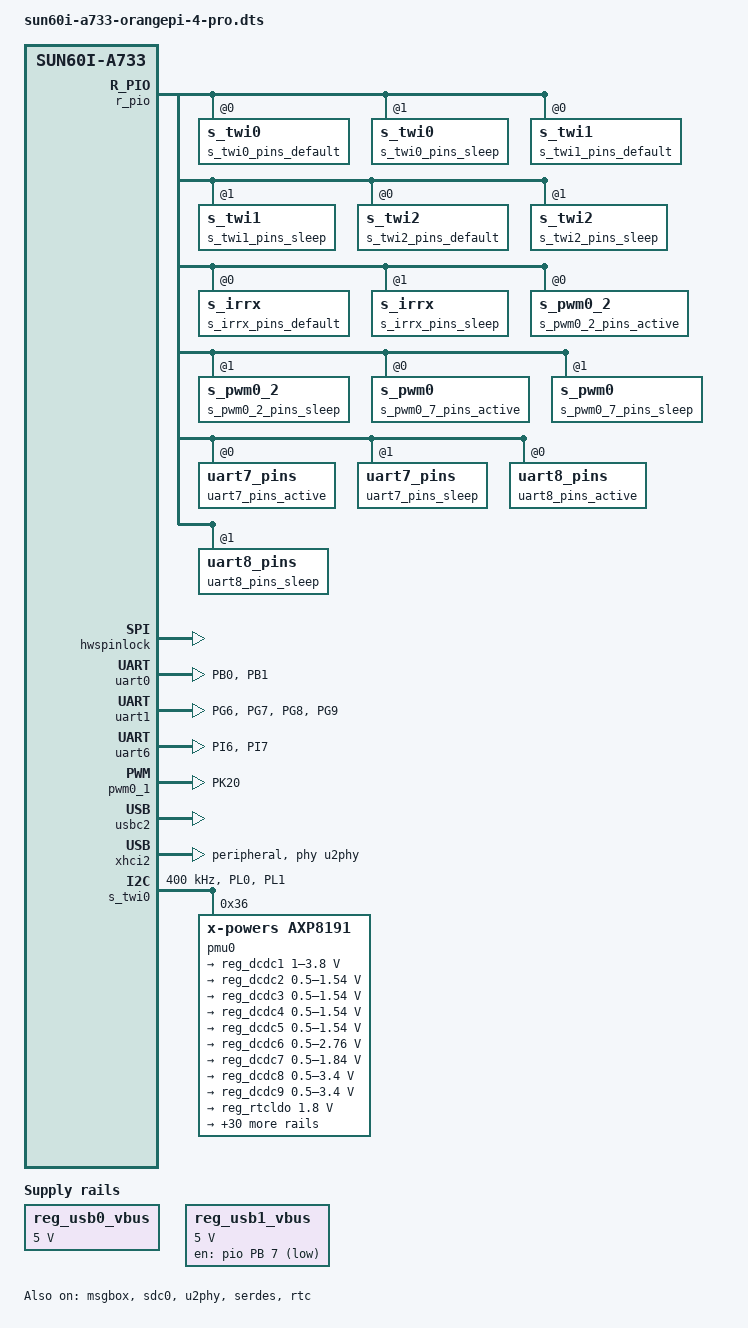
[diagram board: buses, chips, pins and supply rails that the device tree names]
// SPDX-License-Identifier: (GPL-2.0+ or MIT)
//
// Thinned for USB-device-only programmer image (FunctionFS bulk in/out only).
//
// KEPT:  usbc2/xhci2 (dr_mode=peripheral, USB3.0 device on a600000-xhci),
//        u2phy, serdes/combophy0 (USB3 serdes), sdc0, sdc2, ufs,
//        pio/r_pio (GPIO), twi* / s_twi* (I2C), uart* (UART).
//
// USB gadget: ONLY FunctionFS (CONFIG_USB_F_FS + CONFIG_USB_CONFIGFS_F_FS).
//   Dropped: ACM, SERIAL, NCM, RNDIS, MASS_STORAGE, UAC1, UVC, HID, PRINTER,
//            USB_ROLE_SWITCH, USB_NET, NET/INET core (no RNDIS/NCM consumer).
//
// DISABLED per build spec:
//   - GPU, NPU
//   - Display (dsi0 already commented out; touchscreen disabled in twi5)
//   - Ethernet / WiFi / BT (addr_mgt + all related PHY/MAC drivers off in .config)
//   - Camera (vind0/csi*/mipi* already commented out)
//   - Sound (es8388 in twi7 disabled; ac101 in s_twi2 already disabled)
//   - PCIe host (AW_PCIE_RC off in .config; serdes retained for USB3)
//   - SPI-NOR (spi0 disabled; AW_MTD_SPI_NOR off in .config)
//   - USB host mode (EHCI/OHCI/XHCI HCDs off in .config; only DWC3-peripheral kept)
//   - LED (gpio-leds status_led disabled; ledc disabled; CONFIG_LEDS_* off in .config)
//   - sdc3 (eMMC) — not in keep-list; only sdc0 / sdc2 / UFS retained
//

/dts-v1/;

#include "sun60iw2p1.dtsi"
//#define TYPEC_DP 1
/{
        board = "A733";
        compatible = "xunlong,orangepi-4-pro", "arm,sun60iw2p1";
        aliases {
                arisc-config = &arisc_config;
                pmu0 = &pmu0;
                bat_supply = &bat_power_supply;
        };

        reg_usb0_vbus: usb0-vbus {
        compatible = "regulator-fixed";
        regulator-name = "usb0-vbus";
        regulator-min-microvolt = <5000000>;
        regulator-max-microvolt = <5000000>;
        //gpio = <&r_pio PL 2 GPIO_ACTIVE_HIGH>;  ← COMMENTED OUT
        //enable-active-high;
        };

        reg_usb1_vbus: usb1-vbus {
                compatible = "regulator-fixed";
                regulator-name = "usb1-vbus";
                regulator-min-microvolt = <5000000>;
                regulator-max-microvolt = <5000000>;
                regulator-enable-ramp-delay = <1000>;
                gpio = <&pio PB 7 GPIO_ACTIVE_LOW>;
                enable-active-low;
        };

        //wifi_power_en: wifi_power_en {
        //      compatible = "regulator-fixed";
        //      regulator-name = "wifi_power_en";
        //      regulator-min-microvolt = <3300000>;
        //      regulator-max-microvolt = <3300000>;
        //      regulator-enable-ramp-delay = <1000>;
        //      gpio = <&pio PB 4 GPIO_ACTIVE_HIGH>;
        //      enable-active-high;
        //      regulator-always-on;
        //      regulator-boot-on;
        //};

        //wifi_chip_en: wifi_chip_en {
        //      compatible = "regulator-fixed";
        //      regulator-name = "wifi_chip_en";
        //      regulator-min-microvolt = <3300000>;
        //      regulator-max-microvolt = <3300000>;
        //      regulator-enable-ramp-delay = <1000>;
        //      gpio = <&r_pio PM 1 GPIO_ACTIVE_HIGH>;
        //      enable-active-high;
        //      regulator-always-on;
        //      regulator-boot-on;
        //};

        //eeprom_wp: eeprom-wp {
        //      compatible = "regulator-fixed";
        //      regulator-name = "eeprom_wp";
        //      regulator-min-microvolt = <3300000>;
        //      regulator-max-microvolt = <3300000>;
        //      regulator-enable-ramp-delay = <1000>;
        //      gpio = <&pio PC 7 GPIO_ACTIVE_HIGH>;
        //      enable-active-high;
        //      regulator-always-on;
        //      regulator-boot-on;
        //};

        arisc_config: arisc_config {
                s_uart_config{
                        pins = "PL2", "PL3";
                        function = <3>, <3>;
                        status = "disabled";
                };
        };

        //fan0: pwm-fan {
        //      compatible = "pwm-fan";
        //      #cooling-cells = <2>; 
        //      cooling-levels = <0 18 102 170 255>;
        //      pwms = <&s_pwm0 7 25000 0>;
        //};

        leds {
                compatible = "gpio-leds";
                status = "disabled";   /* thinned: LED removed per build spec */

                led-0 {
                        label = "status_led";
                        gpios = <&pio PB 6 GPIO_ACTIVE_HIGH>;
                        linux,default-trigger = "heartbeat";
                        status = "disabled";
                };

                //led-1 {
                //      label = "radxa:green:power";
                //      gpios = <&pio PJ 26 GPIO_ACTIVE_LOW>;
                //      linux,default-trigger = "default-on";
                //};
        };

};

&ccu {
        clk-init-gate = <1>;
};

&pio {
        //gpio-line-names =
        ///* PA */
        //"", "", "", "",
        //"", "", "", "",
        //"", "", "", "",
        //"", "", "", "",
        //"", "", "", "",
        //"", "", "", "",
        //"", "", "", "",
        //"", "", "", "",
        ///* PB */
        //"PIN_7", "PIN_11", "", "",
        //"", "", "", "",
        //"", "PIN_8", "PIN_10", "",
        //"", "", "", "",
        //"", "", "", "",
        //"", "", "", "",
        //"", "", "", "",
        //"", "", "", "",
        ///* PC */
        //"", "", "", "",
        //"", "", "", "",
        //"", "", "", "",
        //"", "", "", "",
        //"", "", "", "",
        //"", "", "", "",
        //"", "", "", "",
        //"", "", "", "",
        ///* PD */
        //"", "", "", "",
        //"", "", "", "",
        //"", "", "PIN_24", "PIN_23",
        //"PIN_19", "PIN_21", "PIN_26", "",
        //"PIN_28", "PIN_27", "", "",
        //"PIN_32", "", "", "",
        //"", "", "", "",
        //"", "", "", "",
        ///* PE */
        //"", "", "", "",
        //"", "", "", "",
        //"", "", "", "",
        //"", "", "", "",
        //"", "", "", "",
        //"", "", "", "",
        //"", "", "", "",
        //"", "", "", "",
        ///* PF */
        //"", "", "", "",
        //"", "", "", "",
        //"", "", "", "",
        //"", "", "", "",
        //"", "", "", "",
        //"", "", "", "",
        //"", "", "", "",
        //"", "", "", "",
        ///* PG */
        //"", "", "", "",
        //"", "", "", "",
        //"", "", "", "",
        //"", "", "", "",
        //"", "", "", "",
        //"", "", "", "",
        //"", "", "", "",
        //"", "", "", "",
        ///* PH */
        //"", "", "", "",
        //"", "", "", "",
        //"", "", "", "",
        //"", "", "", "",
        //"", "", "", "",
        //"", "", "", "",
        //"", "", "", "",
        //"", "", "", "",
        ///* PI */
        //"", "", "", "",
        //"", "", "", "",
        //"", "", "", "",
        //"", "", "", "",
        //"", "", "", "",
        //"", "", "", "",
        //"", "", "", "",
        //"", "", "", "",
        ///* PJ */
        //"", "", "", "",
        //"", "", "", "",
        //"", "", "", "",
        //"", "", "", "",
        //"", "", "", "",
        //"", "", "PIN_5", "PIN_3",
        //"PIN_16", "PIN_18", "", "",
        //"", "", "", "",
        ///* PK */
        //"PIN_12", "PIN_36", "PIN_35", "PIN_38",
        //"PIN_40", "PIN_29", "PIN_31", "PIN_33",
        //"PIN_37", "", "", "",
        //"", "", "", "",
        //"", "", "", "",
        //"", "", "", "",
        //"", "", "", "",
        //"", "", "", "";

        husb311_int: husb311-int@0 {
                pins = "PD0";
                function = "gpio_in";
                drive-strength = <10>;
                bias-pull-up;
        };

        uart0_pins_active: uart0_pins@0 {
                pins = "PB0", "PB1";
                function = "uart0";
                drive-strength = <10>;
        };

        uart0_pins_sleep: uart0_pins@1 {
                pins = "PB0", "PB1";
                function = "gpio_in";
                drive-strength = <10>;
        };

        uart1_pins_active: uart1_pins@0 {
                pins = "PG6", "PG7", "PG8", "PG9";
                function = "uart1";
                drive-strength = <10>;
        };

        uart1_pins_sleep: uart1_pins@1 {
                pins = "PG6", "PG7", "PG8", "PG9";
                function = "io_disabled";
                drive-strength = <10>;
        };

        uart2_pins_active: uart2_pins@0 {
                pins = "PB0", "PB1", "PB2", "PB3";
                function = "uart2";
                drive-strength = <10>;
        };

        uart2_pins_sleep: uart2_pins@1 {
                pins = "PB0", "PB1", "PB2", "PB3";
                function = "io_disabled";
                drive-strength = <10>;
        };

        uart3_pins_active: uart3_pins@0 {
                pins = "PI1", "PI12";
                function = "uart3";
                drive-strength = <10>;
        };

        uart3_pins_sleep: uart3_pins@1 {
                pins = "PI11", "PI12";
                function = "io_disabled";
                drive-strength = <10>;
        };

        uart5_pins_active: uart5_pins@0 {
                pins = "", "";
                function = "uart5";
                drive-strength = <10>;
        };

        uart5_pins_sleep: uart5_pins@1 {
                pins = "", "";
                function = "io_disabled";
                drive-strength = <10>;
        };

        uart6_pins_active: uart6_pins@0 {
                pins = "PI6", "PI7";
                function = "uart6";
                drive-strength = <10>;
        };

        uart6_pins_sleep: uart6_pins@1 {
                pins = "PI6", "PI7";
                function = "io_disabled";
                drive-strength = <10>;
        };

        pwm0_1_pins_active: pwm0_1@0 {
                pins = "PK20";
                function = "pwm0_1";
                drive-strength = <10>;
        };

        pwm0_1_pins_sleep: pwm0_1@1 {
                pins = "PK20";
                function = "gpio_in";
                bias-pull-down;
        };

        pwm0_0_pins_active: pwm0_0@0 {
                pins = "PD0";
                function = "pwm0_0";
                drive-strength = <10>;
        };

        pwm0_0_pins_sleep: pwm0_0@1 {
                pins = "PD0";
                function = "gpio_in";
                bias-pull-down;
        };

        pwm0_2_pins_active: pwm0_2@0 {
                pins = "PD2";
                function = "pwm0_2";
                drive-strength = <10>;
        };

        pwm0_2_pins_sleep: pwm0_2@1 {
                pins = "PD2";
                function = "gpio_in";
                bias-pull-down;
        };

        pwm0_3_pins_active: pwm0_3@0 {
                pins = "PD3";
                function = "pwm0_3";
                drive-strength = <10>;
        };

        pwm0_3_pins_sleep: pwm0_3@1 {
                pins = "PD3";
                function = "gpio_in";
                bias-pull-down;
        };

        pwm0_4_pins_active: pwm0_4@0 {
                pins = "PD4";
                function = "pwm0_4";
                drive-strength = <10>;
        };

        pwm0_4_pins_sleep: pwm0_4@1 {
                pins = "PD4";
                function = "gpio_in";
                bias-pull-down;
        };

        pwm0_5_pins_active: pwm0_5@0 {
                pins = "PD5";
                function = "pwm0_5";
                drive-strength = <10>;
        };

        pwm0_5_pins_sleep: pwm0_5@1 {
                pins = "PD5";
                function = "gpio_in";
                bias-pull-down;
        };

        pwm0_6_pins_active: pwm0_6@0 {
                pins = "PD6";
                function = "pwm0_6";
                drive-strength = <10>;
        };

        pwm0_6_pins_sleep: pwm0_6@1 {
                pins = "PD6";
                function = "gpio_in";
                bias-pull-down;
        };

        pwm0_7_pins_active: pwm0_7@0 {
                pins = "PD7";
                function = "pwm0_7";
                drive-strength = <10>;
        };

        pwm0_7_pins_sleep: pwm0_7@1 {
                pins = "PD7";
                function = "gpio_in";
                bias-pull-down;
        };

        pwm1_8_pins_active: pwm1@0 {
                pins = "PJ26";
                function = "pwm1_8";
                drive-strength = <10>;
        };

        pwm1_8_pins_sleep: pwm1@1 {
                pins = "PJ26";
                function = "gpio_in";
                bias-pull-down;
        };

        pwm1_3_pins_active: pwm1@0 {
                pins = "PG2";
                function = "pwm1_3";
                drive-strength = <10>;
        };

        pwm1_3_pins_sleep: pwm1@1 {
                pins = "PG2";
                function = "gpio_in";
                bias-pull-down;
        };

        pwm1_9_pins_active: pwm1@0 {
                pins = "PK5";
                function = "pwm1_9";
                drive-strength = <10>;
        };

        pwm1_9_pins_sleep: pwm1@1 {
                pins = "PK5";
                function = "gpio_in";
                bias-pull-down;
        };

        pwm1_6_pins_active: pwm6@0 {
                pins = "PI15";
                function = "pwm1_6";
                drive-strength = <10>;
        };

        pwm1_6_pins_sleep: pwm6@1 {
                pins = "PI15";
                function = "gpio_in";
                bias-pull-down;
        };

        twi0_pins_default: twi0@0 {
                pins = "PB2", "PB3";
                function = "twi0";
                drive-strength = <10>;
                bias-pull-up;
        };

        twi0_pins_sleep: twi0@1 {
                pins = "PB2", "PB3";
                function = "gpio_in";
        };

        twi1_pins_default: twi1@0 {
                pins = "PB4", "PB5";
                function = "twi1";
                drive-strength = <10>;
                bias-pull-up;
        };

        twi1_pins_sleep: twi1@1 {
                pins = "PB4", "PB5";
                function = "gpio_in";
        };

        twi2_pins_default: twi2@0 {
                pins = "PE1", "PE2";
                function = "twi2";
                drive-strength = <10>;
                bias-pull-up;
        };

        twi2_pins_sleep: twi2@1 {
                pins = "PE1", "PE2";
                function = "gpio_in";
        };

        twi3_pins_default: twi3@0 {
                pins = "PE3", "PE4";
                function = "twi3";
                drive-strength = <10>;
                bias-pull-up;
        };

        twi3_pins_sleep: twi3@1 {
                pins = "PE3", "PE4";
                function = "gpio_in";
        };

        twi5_pins_default: twi5@0 {
                pins = "PJ26", "PJ27";
                function = "twi5";
                drive-strength = <10>;
                bias-pull-up;
        };

        twi5_pins_sleep: twi5@1 {
                pins = "PJ26", "PJ27";
                function = "gpio_in";
        };

        twi7_pins_default: twi7@0 {
                pins = "PJ22", "PJ23";
                function = "twi7";
                drive-strength = <10>;
                bias-pull-up;
        };

        twi7_pins_sleep: twi7@1 {
                pins = "PJ22", "PJ23";
                function = "gpio_in";
        };

        twi8_pins_default: twi8@0 {
                pins = "PB9", "PB10";
                function = "twi8";
                drive-strength = <10>;
                bias-pull-up;
        };

        twi8_pins_sleep: twi8@1 {
                pins = "PB9", "PB10";
                function = "gpio_in";
        };

        twi9_pins_default: twi9@0 {
                pins = "PE14", "PE15";
                function = "twi9";
                drive-strength = <40>;
                bias-pull-up;
        };

        twi9_pins_sleep: twi9@1 {
                pins = "PE14", "PE15";
                function = "gpio_in";
        };

        twi11_pins_default: twi11@0 {
                pins = "PI4", "PI5";
                function = "twi11";
                drive-strength = <10>;
                bias-pull-up;
        };

        twi11_pins_sleep: twi11@1 {
                pins = "PI4", "PI5";
                function = "gpio_in";
        };

        /* i2s0 pins */
        i2s0_pins_a: i2s0@0 {
                pins = "PB4";
                function = "i2s0_mclk";
                allwinner,drive = <1>;
                bias-disable;
        };

        i2s0_pins_b: i2s0@1 {
                pins = "PB5";
                function = "i2s0_bclk";
                allwinner,drive = <1>;
                bias-disable;
        };

        i2s0_pins_c: i2s0@2 {
                pins = "PB6";
                function = "i2s0_lrck";
                allwinner,drive = <1>;
                bias-disable;
        };

        i2s0_pins_e: i2s0@4 {
                pins = "PB7";
                function = "i2s0_dout0";
                allwinner,drive = <1>;
                bias-pull-down;
        };

        i2s0_pins_d: i2s0@3 {
                pins = "PB8";
                function = "i2s0_din0";
                allwinner,drive = <1>;
                bias-pull-down;
        };

        i2s0_pins_f: i2s0@5 {
                pins = "PB4", "PB5", "PB6", "PB7", "PB8";
                function = "io_disabled";
                allwinner,drive = <1>;
                bias-disable;
        };

        /* i2s1 pins */
        i2s1_pins_a: i2s1@0 {
                pins = "PG10";
                function = "i2s1_mclk";
                allwinner,drive = <1>;
                bias-disable;
        };

        i2s1_pins_b: i2s1@1 {
                pins = "PG11";
                function = "i2s1_bclk";
                allwinner,drive = <1>;
                bias-disable;
        };

        i2s1_pins_c: i2s1@2 {
                pins = "PG12";
                function = "i2s1_lrck";
                allwinner,drive = <1>;
                bias-disable;
        };

        i2s1_pins_d: i2s1@3 {
                pins = "PG13";
                function = "i2s1_dout0";
                allwinner,drive = <1>;
                bias-disable;
        };

        i2s1_pins_e: i2s1@4 {
                pins = "PG14";
                function = "i2s1_din0";
                allwinner,drive = <1>;
                bias-disable;
        };

        i2s1_pins_f: i2s1@5 {
                pins = "PG10", "PG11", "PG12", "PG13", "PG14";
                function = "io_disabled";
                allwinner,drive = <1>;
                bias-disable;
        };

        /* i2s2 pins */
        i2s2_pins_b: i2s2@1 {
                pins = "PH3";
                function = "i2s2_bclk";
                allwinner,drive = <1>;
                bias-disable;
        };

        i2s2_pins_c: i2s2@2 {
                pins = "PH4";
                function = "i2s2_lrck";
                allwinner,drive = <1>;
                bias-disable;
        };

        i2s2_pins_d: i2s2@3 {
                pins = "PH6";
                function = "i2s2_din0";
                allwinner,drive = <1>;
                bias-disable;
        };

        i2s2_pins_e: i2s2@4 {
                pins = "PH5";
                function = "i2s2_dout0";
                allwinner,drive = <1>;
                bias-disable;
        };

        i2s2_pins_f: i2s2@5 {
                pins = "PH3", "PH4", "PH5", "PH6";
                function = "io_disabled";
                allwinner,drive = <1>;
                bias-disable;
        };

        /* i2s3 pins */
        i2s3_pins_a: i2s3@0 {
                pins = "PE7";
                function = "i2s3_bclk";
                allwinner,drive = <1>;
                bias-disable;
        };

        i2s3_pins_b: i2s3@1 {
                pins = "PE8";
                function = "i2s3_lrck";
                allwinner,drive = <1>;
                bias-disable;
        };

        i2s3_pins_c: i2s3@2 {
                pins = "PE9";
                function = "i2s3_mclk";
                allwinner,drive = <1>;
                bias-disable;
        };

        i2s3_pins_d: i2s1@3 {
                pins = "PE10";
                function = "i2s3_din3";
                allwinner,drive = <1>;
                bias-disable;
        };

        i2s3_pins_e: i2s3@4 {
                pins = "PE11";
                function = "i2s3_dout2";
                allwinner,drive = <1>;
                bias-disable;
        };

        i2s3_pins_f: i2s3@5 {
                pins = "PE7", "PE8", "PE9", "PE10", "PE11";
                function = "io_disabled";
                allwinner,drive = <1>;
                bias-disable;
        };

        /* i2s4 pins */
        i2s4_pins_a: i2s4@0 {
                pins = "PK1";
                function = "i2s4_mclk";
                drive-strength = <20>;
                bias-disable;
        };

        i2s4_pins_b: i2s4@1 {
                pins = "PK0";
                function = "i2s4_bclk";
                drive-strength = <20>;
                bias-disable;
        };

        i2s4_pins_c: i2s4@2 {
                pins = "PK2";
                function = "i2s4_lrck";
                drive-strength = <20>;
                bias-disable;
        };

        i2s4_pins_d: i2s4@3 {
                pins = "PK4";
                function = "i2s4_dout0";
                drive-strength = <20>;
                bias-disable;
        };

        i2s4_pins_e: i2s4@4 {
                pins = "PK3";
                function = "i2s4_din0";
                drive-strength = <20>;
                bias-disable;
        };

        i2s4_pins_f: i2s4@5 {
                pins = "PK0", "PK1", "PK2", "PK3", "PK4";
                function = "io_disabled";
                drive-strength = <20>;
                bias-disable;
        };

        owa_pins_a: owa@0 {
                pins = "PI10";
                function = "owa0";
                allwinner,drive = <1>;
                bias-disable;
        };

        owa_pins_b: owa@1 {
                pins = "PI10";
                function = "io_disabled";
                allwinner,drive = <1>;
                bias-disable;
        };

        gmac0_pins_default: gmac0@0 {
                pins = "PH0", "PH1", "PH2", "PH3", "PH4", "PH5", "PH6", "PH7",
                        "PH8", "PH9", "PH10", "PH11", "PH12","PH13", "PH14", "PH15";
                function = "rgmii0";
                allwinner,drive = <1>;
                bias-pull-up;
        };

        gmac0_pins_sleep: gmac0@1 {
                pins = "PH0", "PH1", "PH2", "PH3", "PH4", "PH5", "PH6", "PH7",
                        "PH8", "PH9", "PH10", "PH11", "PH12","PH13", "PH14", "PH15";
                function = "io_disabled";
        };

        spi0_pins_default: spi0@0 {
                pins = "PC12", "PC2", "PC4"; /* clk, mosi, miso */
                function = "spi0";
                allwinner,drive = <1>;
                //drive-strength = <20>;
        };

        spi0_pins_cs: spi0@1 {
                pins = "PC3"; /* cs */
                function = "spi0";
                allwinner,drive = <1>;
                //drive-strength = <20>;
                bias-pull-up;
        };

        spi0_pins_sleep: spi0@2 {
                pins = "PC12", "PC2", "PC4", "PC3";
                function = "io_disabled";
        };

        spi3_pin_default: spi3_pin_default{
                pins = "PE1","PE2","PE3","PE4","PE12";
                function = "spi3";
        };

        spi3_pin_sleep: spi3_pin_sleep{
                pins = "PE1","PE2","PE3","PE4","PE12";
                function = "gpio_in";
        };

        ledc_pins_a: ledc@0 {
                pins = "PE4";
                function = "ledc";
                drive-strength = <10>;
        };

        ledc_pins_b: ledc@1 {
                pins = "PE4";
                function = "gpio_in";
        };
};

&r_pio {
        //gpio-line-names =
        ///* PL */
        //"", "", "", "",
        //"", "", "PIN_13", "PIN_15",
        //"", "", "PIN_22", "",
        //"", "", "", "",
        //"", "", "", "",
        //"", "", "", "",
        //"", "", "", "",
        //"", "", "", "",
        ///* PM */
        //"", "", "", "",
        //"", "", "", "",
        //"", "", "", "",
        //"", "", "", "",
        //"", "", "", "",
        //"", "", "", "",
        //"", "", "", "",
        //"", "", "", "",
        ///* PN */
        //"", "", "", "",
        //"", "", "", "",
        //"", "", "", "",
        //"", "", "", "",
        //"", "", "", "",
        //"", "", "", "",
        //"", "", "", "",
        //"", "", "", "";

        s_twi0_pins_default: s_twi0@0 {
                pins = "PL0", "PL1";
                function = "s_twi0";
                drive-strength = <10>;
                bias-pull-up;
        };

        s_twi0_pins_sleep: s_twi0@1 {
                pins = "PL0", "PL1";
                function = "gpio_in";
        };

        s_twi1_pins_default: s_twi1@0 {
                pins = "PL12", "PL13";
                function = "s_twi1";
                drive-strength = <30>;
                //bias-pull-up;
        };

        s_twi1_pins_sleep: s_twi1@1 {
                pins = "PL12", "PL13";
                function = "gpio_in";
        };

        s_twi2_pins_default: s_twi2@0 {
                pins = "PL10", "PL11";
                function = "s_twi2";
                drive-strength = <10>;
                bias-pull-up;
        };

        s_twi2_pins_sleep: s_twi2@1 {
                pins = "PL10", "PL11";
                function = "gpio_in";
        };

        s_irrx_pins_default: s_irrx@0 {
                pins = "PL4";
                function = "s_ir_rx";
        };

        s_irrx_pins_sleep: s_irrx@1 {
                pins = "PL4";
                function = "gpio_in";
        };

        s_pwm0_2_pins_active:s_pwm0_2@0 {
                pins = "PL4";
                function = "s_pwm0_2";
                drive-strength = <10>;
        };

        s_pwm0_2_pins_sleep:s_pwm0_2@1 {
                pins = "PL4";
                function = "gpio_in";
                bias-pull-down;
        };

        s_pwm0_7_pins_active:s_pwm0@0 {
                pins = "PL9";
                function = "s_pwm0_7";
                drive-strength = <10>;
        };

        s_pwm0_7_pins_sleep:s_pwm0@1 {
                pins = "PL9";
                function = "gpio_in";
                bias-pull-down;
        };

        uart7_pins_active: uart7_pins@0 {
                pins = "PL6", "PL7";
                function = "s_uart0";
                drive-strength = <10>;
        };

        uart7_pins_sleep: uart7_pins@1 {
                pins = "PL6","PL7";
                function = "io_disabled";
                drive-strength = <10>;
        };

        uart8_pins_active: uart8_pins@0 {
                pins = "PL8", "PL9";
                function = "s_uart1";
                drive-strength = <10>;
        };

        uart8_pins_sleep: uart8_pins@1 {
                pins = "PL8","PL9";
                function = "io_disabled";
                drive-strength = <10>;
        };

};

&soc {
        auto_print@54321 {
                reg = <0x0 0x54321 0x0 0x0>;
                device_type = "auto_print";
                status = "okay";
        };
};

&msgbox {
        status = "okay";
};

&hwspinlock {
        status = "okay";
};

&uart0 {
        pinctrl-names = "default", "sleep";
        pinctrl-0 = <&uart0_pins_active>;
        pinctrl-1 = <&uart0_pins_sleep>;
        status = "okay";
};

&uart1 {
        pinctrl-names = "default", "sleep";
        pinctrl-0 = <&uart1_pins_active>;
        pinctrl-1 = <&uart1_pins_sleep>;
        status = "okay";
};

//&s_uart0 {
//      pinctrl-names = "default", "sleep";
//      pinctrl-0 = <&s_uart0_pins_active>;
//      pinctrl-1 = <&s_uart0_pins_sleep>;
//      status = "disabled";
//};
//
//&s_uart1 {
//      pinctrl-names = "default", "sleep";
//      pinctrl-0 = <&s_uart1_pins_active>;
//      pinctrl-1 = <&s_uart1_pins_sleep>;
//      status = "disabled";
//};

&uart2 {
        pinctrl-names = "default", "sleep";
        pinctrl-0 = <&uart2_pins_active>;
        pinctrl-1 = <&uart2_pins_sleep>;
        status = "disabled";
};

&uart3 {
        pinctrl-names = "default", "sleep";
        pinctrl-0 = <&uart3_pins_active>;
        pinctrl-1 = <&uart3_pins_sleep>;
        status = "disabled";
};

&uart5 {
        pinctrl-names = "default", "sleep";
        pinctrl-0 = <&uart5_pins_active>;
        pinctrl-1 = <&uart5_pins_sleep>;
        status = "disabled";
};

&uart6 {
        pinctrl-names = "default", "sleep";
        pinctrl-0 = <&uart6_pins_active>;
        pinctrl-1 = <&uart6_pins_sleep>;
        status = "okay";
};

&uart7 {
        pinctrl-names = "default", "sleep";
        pinctrl-0 = <&uart7_pins_active>;
        pinctrl-1 = <&uart7_pins_sleep>;
        status = "disabled";
};

&uart8 {
        pinctrl-names = "default", "sleep";
        pinctrl-0 = <&uart8_pins_active>;
        pinctrl-1 = <&uart8_pins_sleep>;
        status = "disabled";
};

&pwm0_0 {
        pinctrl-names = "active", "sleep";
        pinctrl-0 = <&pwm0_0_pins_active>;
        pinctrl-1 = <&pwm0_0_pins_sleep>;
        status = "disabled";
};

&pwm0_1 {
        pinctrl-names = "active", "sleep";
        pinctrl-0 = <&pwm0_1_pins_active>;
        pinctrl-1 = <&pwm0_1_pins_sleep>;
        status = "okay";
};

&pwm0_2 {
        pinctrl-names = "active", "sleep";
        pinctrl-0 = <&pwm0_2_pins_active>;
        pinctrl-1 = <&pwm0_2_pins_sleep>;
        status = "disabled";
};

&pwm0_3 {
        pinctrl-names = "active", "sleep";
        pinctrl-0 = <&pwm0_3_pins_active>;
        pinctrl-1 = <&pwm0_3_pins_sleep>;
        status = "disabled";
};

&pwm0_4 {
        pinctrl-names = "active", "sleep";
        pinctrl-0 = <&pwm0_4_pins_active>;
        pinctrl-1 = <&pwm0_4_pins_sleep>;
        status = "disabled";
};

&pwm0_5 {
        pinctrl-names = "active", "sleep";
        pinctrl-0 = <&pwm0_5_pins_active>;
        pinctrl-1 = <&pwm0_5_pins_sleep>;
        status = "disabled";
};

&pwm0_6 {
        pinctrl-names = "active", "sleep";
        pinctrl-0 = <&pwm0_6_pins_active>;
        pinctrl-1 = <&pwm0_6_pins_sleep>;
        status = "disabled";
};

&pwm0_7 {
        pinctrl-names = "active", "sleep";
        pinctrl-0 = <&pwm0_7_pins_active>;
        pinctrl-1 = <&pwm0_7_pins_sleep>;
        status = "disabled";
};

&pwm1_3 {
        pinctrl-names = "active", "sleep";
        pinctrl-0 = <&pwm1_3_pins_active>;
        pinctrl-1 = <&pwm1_3_pins_sleep>;
        status = "disabled";
};

&pwm1_6 {
        pinctrl-names = "active", "sleep";
        pinctrl-0 = <&pwm1_6_pins_active>;
        pinctrl-1 = <&pwm1_6_pins_sleep>;
        status = "disabled";
};

&pwm1_8 {
        pinctrl-names = "active", "sleep";
        pinctrl-0 = <&pwm1_8_pins_active>;
        pinctrl-1 = <&pwm1_8_pins_sleep>;
        status = "disabled";
};

&pwm1_9 {
        pinctrl-names = "active", "sleep";
        pinctrl-0 = <&pwm1_9_pins_active>;
        pinctrl-1 = <&pwm1_9_pins_sleep>;
        status = "disabled";
};

&s_pwm0_7 {
        pinctrl-names = "active", "sleep";
        pinctrl-0 = <&s_pwm0_7_pins_active>;
        pinctrl-1 = <&s_pwm0_7_pins_sleep>;
        status = "disabled";
};

&s_pwm0_2 {
        pinctrl-names = "active", "sleep";
        pinctrl-0 = <&s_pwm0_2_pins_active>;
        pinctrl-1 = <&s_pwm0_2_pins_sleep>;
        status = "disabled";
};


//&cpul_thermal_zone {
//      cooling-maps {
//              map0 {
//                      trip = <&cpul_target>;
//                      cooling-device = <&cpu0 THERMAL_NO_LIMIT THERMAL_NO_LIMIT>;
//                      contribution = <1024>;
//              };
//
//              map1 {
//                      trip = <&cpul_threshold>;
//                      cooling-device = <&fan0 2 THERMAL_NO_LIMIT>;
//                      contribution = <1024>;
//              };
//      };
//};
//
//&cpub_thermal_zone {
//      cooling-maps {
//              map0 {
//                      trip = <&cpub_target>;
//                      cooling-device = <&cpu6 THERMAL_NO_LIMIT THERMAL_NO_LIMIT>;
//                      contribution = <1024>;
//              };
//
//              map1 {
//                      trip = <&cpub_threshold>;
//                      cooling-device = <&fan0 2 THERMAL_NO_LIMIT>;
//                      contribution = <1024>;
//              };
//      };
//};

/* ── sdc2: Disabled at boot for quiet log; can be enabled at runtime via DT overlay ──
 * Apply /lib/firmware/overlays/sdc2-enable.dtbo via configfs to turn on:
 *   mkdir /sys/kernel/config/device-tree/overlays/sdc2-on
 *   cat /lib/firmware/overlays/sdc2-enable.dtbo > /sys/kernel/config/device-tree/overlays/sdc2-on/dtbo
 * Disable (remove overlay):
 *   rmdir /sys/kernel/config/device-tree/overlays/sdc2-on
 * Requires: CONFIG_OF_OVERLAY=y, CONFIG_OF_CONFIGFS=y (enabled in .config).
 */
&sdc2 {
        status = "disabled";
};

/* ── sdc1: not in keep-list — disable to silence 20+ RTO probe errors (cmd 52/8/5/55/1) ── */
&sdc1 {
        status = "disabled";
};

&sdc0 {
        bus-width = <4>;
        cd-gpios = <&pio PF 6 (GPIO_ACTIVE_LOW | GPIO_PULL_UP)>;
        /*non-removable;*/
        /*broken-cd;*/
        cd-inverted;
        /*data3-detect;*/
        /*card-pwr-gpios = <&pio PH 14 1 1 2 0xffffffff>;*/
        cd-used-24M;
        cd-set-debounce = <0x1>;
        cd-debounce-delay-ms = <40000>;
        cap-sd-highspeed;
        sd-uhs-sdr50;
        sd-uhs-ddr50;
        sd-uhs-sdr104;
        no-sdio;
        no-mmc;
        sunxi-power-save-mode;
        //sunxi-dis-signal-vol-sw;
        execute_tuning_in_kernel;
        //max-frequency = <150000000>;
        max-frequency = <150000000>;
        ctl-spec-caps = <0x428>;
        vmmc-supply = <&reg_dc1sw2>;
        vqmmc33sw-supply = <&reg_dc1sw2>;
        vdmmc33sw-supply = <&reg_dc1sw2>;
        vqmmc18sw-supply = <&reg_cldo5>;
        vdmmc18sw-supply = <&reg_cldo5>;
        status = "okay";
};


#ifdef TYPEC_DP
// &usbc0 {
//      usb-role-switch;
//      port {
//              #address-cells = <1>;
//              #size-cells = <0>;
//              usbc0_role_switch: endpoint@0 {
//                      reg = <0>;
//                      remote-endpoint = <&usbc0_role_sw>;
//              };
//      };
// };
#endif

/*
 * usb_port_type: usb mode. 0-device, 1-host, 2-otg.
 * usb_detect_type: usb hotplug detect mode. 0-none, 1-vbus/id detect, 2-pmu detect, 3-tcpm detect.
 * usb_detect_mode: 0-thread scan, 1-id gpio interrupt, 2-pmu notify.
 * usb_id_gpio: gpio for id detect.
 * usb_det_vbus_gpio: gpio for id detect. gpio or "axp_ctrl".
 * usb_wakeup_suspend：0-SUPER_STANDBY, 1-USB_STANDBY.
 */




/* ── USB1: Host (wakeup source, unchanged) ── */



/* ── USB0 / OTG: DISABLED ──
 * usbc0 (OTG manager) and udc (USB 2.0 device controller) are NOT used.
 * USB device mode is provided exclusively via the USB 3.0 path:
 *   usbc2 (sunxi-plat-dwc3) → xhci2 (snps,dwc3) — dr_mode=peripheral
 * Keeping usbc0/udc disabled avoids duplicate UDC registration and
 * avoids the Type-C / OTG manager overhead we don't need.
 */
&usbc0 {
        status = "disabled";
};

&udc {
        status = "disabled";
};

/* ── USB2/xHCI: USB3 Type-A DEVICE MODE ──
 *
 * usbc2@12 is a PURE LOGICAL/GLUE node — its reg=<0x0 0x12 ...> is just a
 * placeholder ID, NOT a real MMIO address. The real hardware is the child
 * xhci2-controller@6a00000 (reg=0x06a00000, a genuine MMIO base).
 *
 * The BSP cadence-combophy driver has a `.type = "usbc2"` of_match entry
 * (sunxi-specific soft-match hack) that tries to probe usbc2 directly.
 * It calls platform_get_resource(IORESOURCE_MEM, 0) which correctly
 * returns NULL because there's no real register block at 0x12.
 * That triggers: "sunxi-cadence-combophy 12.usbc2: invalid resource (null)"
 *
 * Fix: delete device_type="usbc2" by overriding it with an empty string.
 * The dwc3_sunxi_plat glue driver matches usbc2 via compatible=
 * "allwinner,sunxi-plat-dwc3" (inherited from base dtsi), NOT via
 * device_type, so clearing device_type doesn't break the DWC3 path.
 * The combophy driver's `.type="usbc2"` soft-match then fails to match,
 * so it skips usbc2 and only probes the real serdes@6c00000 node.
 *
 * drvvbus-supply is required because dwc3_sunxi_plat calls
 * devm_regulator_get(dev, "drvvbus") and defers probe if NULL.
 * Point at the always-on fixed regulator; aw,vbus-shared-quirk prevents
 * the glue from actually toggling VBUS via this regulator.
 */
&usbc2 {
        /* Override device_type to break cadence-combophy's .type="usbc2" match */
        device_type = "";
        usb_detect_type = <0x3>;        /* DWC3_DETECT_TYPE_UNKNOWN — skip PMU CC scan */
        usb_detect_mode = <0x3>;        /* DWC3_DETECT_MODE_UNKNOWN */
        aw,vbus-shared-quirk;
        drvvbus-supply = <&reg_usb0_vbus>;
        status = "okay";
};

&xhci2 {
        dr_mode       = "peripheral";
        phys = <&u2phy>, <&combo0_usb>;
        phy-names = "usb2-phy", "usb3-phy";
        assigned-clocks = <&ccu CLK_USB2_SUSPEND>, <&ccu CLK_USB2_MF>;
        assigned-clock-rates = <24000000>, <400000000>;
        maximum-speed = "super-speed";
        status = "okay";
};

&u2phy {
    status = "okay";
};

&combo0_dp {
    status = "disabled";
};

&combo1_pcie {
    status = "disabled";
};

/* ── SerDes / ComboPHY: Enable + fix lane map for USB3 (non-TypeC) ──
 * Use &combophy0 label reference (NOT re-declaring the node) so we MERGE
 * with the base dtsi combophy0@6c01000 definition (which has reg, clocks,
 * and child phy nodes combo0_usb + combo0_dp). Re-declaring the node
 * created a duplicate that confused the phy framework.
 */
&serdes {
    serdes1v8-supply = <&reg_cldo5>;
    status = "okay";
};

&combophy0 {
    lane_invert = <0 0 0 0>;
    lane_remap = <2 3 0 1>;          /* USB3 Type-A lane order, NOT TypeC/DP */
};


&twi0 {
        clock-frequency = <400000>;
        pinctrl-0 = <&twi0_pins_default>;
        pinctrl-1 = <&twi0_pins_sleep>;
        pinctrl-names = "default", "sleep";
        /* For stability and backwards compatibility, we recommend setting ‘twi_drv_used’ to 1 */
        twi_drv_used = <0>;
        no_suspend = <1>;
        twi-supply = <&reg_cldo3>;
        status = "disabled";

                //eeprom@50 {
                //      compatible = "atmel,24c16";
                //      reg = <0x50>;
                //      //num-addresses = <1>;
                //      status = "okay";
                //};
};

&twi1 {
        clock-frequency = <400000>;
        pinctrl-0 = <&twi1_pins_default>;
        pinctrl-1 = <&twi1_pins_sleep>;
        pinctrl-names = "default", "sleep";
        /* For stability and backwards compatibility, we recommend setting ‘twi_drv_used’ to 1 */
        twi_drv_used = <0>;
        no_suspend = <1>;
        status = "disabled";
};

&twi2 {
        clock-frequency = <400000>;
        pinctrl-0 = <&twi2_pins_default>;
        pinctrl-1 = <&twi2_pins_sleep>;
        pinctrl-names = "default", "sleep";
        /* For stability and backwards compatibility, we recommend setting ‘twi_drv_used’ to 1 */
        twi_drv_used = <0>;
        no_suspend = <1>;
        twi-supply = <&reg_bldo1>;
        status = "disabled";
};

&twi3 {
        clock-frequency = <400000>;
        pinctrl-0 = <&twi3_pins_default>;
        pinctrl-1 = <&twi3_pins_sleep>;
        pinctrl-names = "default", "sleep";
        /* For stability and backwards compatibility, we recommend setting ‘twi_drv_used’ to 1 */
        twi_drv_used = <0>;
        no_suspend = <1>;
        twi-supply = <&reg_bldo1>;
        status = "disabled";
};

&twi5 {
        clock-frequency = <400000>;
        pinctrl-0 = <&twi5_pins_default>;
        pinctrl-1 = <&twi5_pins_sleep>;
        pinctrl-names = "default", "sleep";
        /* For stability and backwards compatibility, we recommend setting ‘twi_drv_used’ to 1 */
        twi_drv_used = <1>;
        twi-supply = <&reg_dc1sw2>;
        status = "disabled";   /* thinned: no active client (touchscreen disabled) */

        touchscreen: touchscreen@14 {
                compatible = "goodix,gt9271";
                reg = <0x14>;
                interrupt-parent = <&pio>;
                interrupts = <PJ 25 IRQ_TYPE_LEVEL_HIGH>;
                irq-gpios = <&pio PJ 25 GPIO_ACTIVE_HIGH>;
                reset-gpios = <&pio PG 10 GPIO_ACTIVE_HIGH>;
                touchscreen-inverted-x;
                //touchscreen-inverted-y;
                touchscreen-swapped-x-y;
                touchscreen-size-x = <1280>;
                touchscreen-size-y = <800>;
                status = "disabled";   /* thinned: display-related touchscreen removed */
        };
};

&twi7 {
        clock-frequency = <400000>;
        pinctrl-0 = <&twi7_pins_default>;
        pinctrl-1 = <&twi7_pins_sleep>;
        pinctrl-names = "default", "sleep";
        /* For stability and backwards compatibility, we recommend setting ‘twi_drv_used’ to 1 */
        twi_drv_used = <1>;
        twi-supply = <&reg_bldo2>;
        status = "disabled";   /* thinned: no active client (es8388 disabled) */

        es8388: es8388@10{
                status = "disabled";   /* thinned: sound codec removed per build spec */
                #sound-dai-cells = <0>;
                compatible = "everest,es8388", "everest,es8389";
                reg = <0x10>;
                assigned-clock-rates = <12288000>;
                //pinctrl-names = "default";
                //pinctrl-0 = <&i2s2m1_mclk>;
        };
};

&twi8 {
        clock-frequency = <400000>;
        pinctrl-0 = <&twi8_pins_default>;
        pinctrl-1 = <&twi8_pins_sleep>;
        pinctrl-names = "default", "sleep";
        /* For stability and backwards compatibility, we recommend setting ‘twi_drv_used’ to 1 */
        twi_drv_used = <1>;
        status = "disabled";   /* thinned: no active client */
};

&twi9 {
        clock-frequency = <100000>;
        pinctrl-0 = <&twi9_pins_default>;
        pinctrl-1 = <&twi9_pins_sleep>;
        pinctrl-names = "default", "sleep";
        /* For stability and backwards compatibility, we recommend setting ‘twi_drv_used’ to 1 */
        twi_drv_used = <1>;
        twi-supply = <&reg_bldo1>;
        status = "disabled";   /* thinned: no active client */
};

&twi11 {
        clock-frequency = <400000>;
        pinctrl-0 = <&twi11_pins_default>;
        pinctrl-1 = <&twi11_pins_sleep>;
        pinctrl-names = "default", "sleep";
        /* For stability and backwards compatibility, we recommend setting ‘twi_drv_used’ to 1 */
        twi_drv_used = <1>;
        twi-supply = <&reg_dc1sw2>;
        status = "disabled";
};

&s_twi0 {
        clock-frequency = <400000>;
        pinctrl-0 = <&s_twi0_pins_default>;
        pinctrl-1 = <&s_twi0_pins_sleep>;
        pinctrl-names = "default", "sleep";
        /* For stability and backwards compatibility, we recommend setting ‘twi_drv_used’ to 1 */
        twi_drv_used = <1>;
        //twi-supply = <&reg_aldo1>;
        no_suspend = <1>;
        status = "okay";

        pmu1: pmu@34 {
                compatible = "x-powers,axp515";
                reg = <0x34>;
                status = "disabled";   /* thinned: unused secondary PMIC, IRQ config fails */
                interrupts = <0 IRQ_TYPE_LEVEL_LOW>;
                interrupt-parent = <&nmi_intc>;
                x-powers,drive-vbus-en;
                pmu_irq_wakeup = <1>;
                pmu_hot_shutdown = <1>;

                wakeup-source;

                powerkey0: powerkey@0 {
                        status = "okay";
                        compatible = "x-powers,axp515-pek";
                        pmu_powkey_off_time = <6000>;
                        pmu_powkey_off_func = <0>;
                        pmu_powkey_off_en = <1>;
                        pmu_powkey_long_time = <1500>;
                        pmu_powkey_on_time = <512>;
                        wakeup_rising;
                        wakeup_falling;
                };

                usb_power_supply: usb_power_supply {
                        compatible = "x-powers,axp515-usb-power-supply";
                        status = "okay";

                        pmu_usbpc_vol = <4600>;
                        pmu_usbpc_cur = <500>;
                        pmu_usbad_vol = <4600>;
                        pmu_usbad_cur = <2500>;
                        pmu_usb_typec_used = <1>;
                        wakeup_usb_in;
                        wakeup_usb_out;
                        wakeup_typec_in;
                        wakeup_typec_out;
                };

                bat_power_supply: bat-power-supply {
                        compatible = "x-powers,axp515-bat-power-supply";
                        status = "okay";
                        pmu_chg_ic_temp = <0>;

                        pmu_battery_rdc= <88>;
                        pmu_battery_cap = <7085>;
                        pmu_runtime_chgcur = <1000>;
                        pmu_suspend_chgcur = <1500>;
                        pmu_shutdown_chgcur = <1500>;
                        pmu_init_chgvol = <4350>;
                        pmu_battery_warning_level1 = <15>;
                        pmu_battery_warning_level2 = <0>;
                        pmu_chgled_func = <0>;
                        pmu_chgled_type = <0>;
                        pmu_bat_para1 = <0>;
                        pmu_bat_para2 = <0>;
                        pmu_bat_para3 = <0>;
                        pmu_bat_para4 = <0>;
                        pmu_bat_para5 = <1>;
                        pmu_bat_para6 = <2>;
                        pmu_bat_para7 = <2>;
                        pmu_bat_para8 = <2>;
                        pmu_bat_para9 = <3>;
                        pmu_bat_para10 = <7>;
                        pmu_bat_para11 = <12>;
                        pmu_bat_para12 = <15>;
                        pmu_bat_para13 = <20>;
                        pmu_bat_para14 = <25>;
                        pmu_bat_para15 = <32>;
                        pmu_bat_para16 = <37>;
                        pmu_bat_para17 = <43>;
                        pmu_bat_para18 = <51>;
                        pmu_bat_para19 = <57>;
                        pmu_bat_para20 = <61>;
                        pmu_bat_para21 = <65>;
                        pmu_bat_para22 = <70>;
                        pmu_bat_para23 = <73>;
                        pmu_bat_para24 = <78>;
                        pmu_bat_para25 = <81>;
                        pmu_bat_para26 = <85>;
                        pmu_bat_para27 = <88>;
                        pmu_bat_para28 = <92>;
                        pmu_bat_para29 = <93>;
                        pmu_bat_para30 = <96>;
                        pmu_bat_para31 = <98>;
                        pmu_bat_para32 = <100>;

                        pmu_bat_temp_enable = <0>;
                        pmu_jetia_en        = <0>;
                        pmu_bat_charge_ltf = <1695>; //-5
                        pmu_bat_charge_htf = <151>; //60
                        pmu_bat_shutdown_ltf = <2125>; //-10
                        pmu_bat_shutdown_htf = <131>; //65
                        pmu_jetia_cool = <1361>; //0
                        pmu_jetia_warm = <208>; //50
                        pmu_jcool_ifall = <1>;//50%
                        pmu_jwarm_ifall = <1>;//50%
                        pmu_bat_temp_para1 = <4378>; //Murata -25
                        pmu_bat_temp_para2 = <2682>; //-15
                        pmu_bat_temp_para3 = <2125>; //-10
                        pmu_bat_temp_para4 = <1695>; //-5
                        pmu_bat_temp_para5 = <1361>;//0
                        pmu_bat_temp_para6 = <1101>; //5
                        pmu_bat_temp_para7 = <896>; //10
                        pmu_bat_temp_para8 = <604>; //20
                        pmu_bat_temp_para9 = <416>; //30
                        pmu_bat_temp_para10 = <292>; //40
                        pmu_bat_temp_para11 = <246>; //45
                        pmu_bat_temp_para12 = <208>; //50
                        pmu_bat_temp_para13 = <177>; //55
                        pmu_bat_temp_para14 = <151>; //60
                        pmu_bat_temp_para15 = <111>; //70
                        pmu_bat_temp_para16 = <83>; //80

                        wakeup_bat_out;
                        wakeup_new_soc;
                        /* wakeup_bat_in; */
                        /* wakeup_bat_charging; */
                        /* wakeup_bat_charge_over; */
                        /* wakeup_low_warning1; */
                        /* wakeup_low_warning2; */
                        wakeup_bat_untemp_work;
                        wakeup_bat_ovtemp_work;
                        /* wakeup_bat_untemp_chg; */
                        /* wakeup_bat_ovtemp_chg; */
                };

                regulator1: regulators@1 {
                        compatible = "x-powers,axp515-regulator";
                        /* drivevbus removed — aw,vbus-shared-quirk handles VBUS */
                };
        };

        pmu0: pmu@36 {
                compatible = "x-powers,axp8191";
                reg = <0x36>;
                status = "okay";
                interrupts = <0 IRQ_TYPE_LEVEL_LOW>;
                interrupt-parent = <&nmi_intc>;
                pmu_reset = <0>;
                pmu_irq_wakeup = <1>;
                pmu_hot_shutdown = <1>;

                powerkey1: powerkey@1 {
                        compatible = "x-powers,axp2101-pek";
                        status = "okay";
                };

                regulator0: regulators@0 {
                        reg_dcdc1: dcdc1 {
                                regulator-name = "axp8191-dcdc1";
                                regulator-min-microvolt = <1000000>;
                                regulator-max-microvolt = <3800000>;
                                regulator-enable-ramp-delay = <1000>;
                                regulator-ramp-delay = <250>;
                                regulator-boot-on;
                                regulator-always-on;
                        };
                        reg_dcdc2: dcdc2 {
                                regulator-name = "axp8191-dcdc2";
                                regulator-min-microvolt = <500000>;
                                regulator-max-microvolt = <1540000>;
                                regulator-ramp-delay = <250>;
                                regulator-enable-ramp-delay = <1000>;
                                regulator-boot-on;
                                regulator-always-on;
                        };
                        reg_dcdc3: dcdc3 {
                                regulator-name = "axp8191-dcdc3";
                                regulator-min-microvolt = <500000>;
                                regulator-max-microvolt = <1540000>;
                                regulator-ramp-delay = <250>;
                                regulator-enable-ramp-delay = <1000>;
                                regulator-boot-on;
                                regulator-always-on;
                        };
                        reg_dcdc4: dcdc4 {
                                regulator-name = "axp8191-dcdc4";
                                regulator-min-microvolt = <500000>;
                                regulator-max-microvolt = <1540000>;
                                regulator-ramp-delay = <250>;
                                regulator-enable-ramp-delay = <1000>;
                                regulator-boot-on;
                                regulator-always-on;
                        };
                        reg_dcdc5: dcdc5 {
                                regulator-name = "axp8191-dcdc5";
                                regulator-min-microvolt = <500000>;
                                regulator-max-microvolt = <1540000>;
                                regulator-ramp-delay = <250>;
                                regulator-enable-ramp-delay = <1000>;
                                regulator-boot-on;
                                regulator-always-on;
                        };
                        reg_dcdc6: dcdc6 {
                                regulator-name = "axp8191-dcdc6";
                                regulator-min-microvolt = <500000>;
                                regulator-max-microvolt = <2760000>;
                                regulator-ramp-delay = <250>;
                                regulator-enable-ramp-delay = <1000>;
                                regulator-boot-on;
                                regulator-always-on;
                        };
                        reg_dcdc7: dcdc7 {
                                regulator-name = "axp8191-dcdc7";
                                regulator-min-microvolt = <500000>;
                                regulator-max-microvolt = <1840000>;
                                regulator-ramp-delay = <250>;
                                regulator-enable-ramp-delay = <1000>;
                                regulator-boot-on;
                                regulator-always-on;
                        };
                        reg_dcdc8: dcdc8 {
                                regulator-name = "axp8191-dcdc8";
                                regulator-min-microvolt = <500000>;
                                regulator-max-microvolt = <3400000>;
                                regulator-ramp-delay = <250>;
                                regulator-enable-ramp-delay = <1000>;
                                regulator-boot-on;
                                regulator-always-on;
                        };
                        reg_dcdc9: dcdc9 {
                                regulator-name = "axp8191-dcdc9";
                                regulator-min-microvolt = <500000>;
                                regulator-max-microvolt = <3400000>;
                                regulator-ramp-delay = <250>;
                                regulator-enable-ramp-delay = <1000>;
                                regulator-boot-on;
                                regulator-always-on;
                        };
                        reg_rtcldo: rtcldo {
                                /* RTC_LDO is a fixed, always-on regulator */
                                regulator-name = "axp8191-rtcldo";
                                regulator-min-microvolt = <1800000>;
                                regulator-max-microvolt = <1800000>;
                                regulator-boot-on;
                                regulator-always-on;
                        };
                        reg_aldo1: aldo1 {
                                regulator-name = "axp8191-aldo1";
                                regulator-min-microvolt = <500000>;
                                regulator-max-microvolt = <3400000>;
                                regulator-enable-ramp-delay = <1000>;
                                regulator-boot-on;
                                regulator-always-on;
                        };
                        reg_aldo2: aldo2 {
                                regulator-name = "axp8191-aldo2";
                                regulator-min-microvolt = <500000>;
                                regulator-max-microvolt = <3400000>;
                                regulator-enable-ramp-delay = <1000>;
                        };
                        reg_aldo3: aldo3 {
                                regulator-name = "axp8191-aldo3";
                                regulator-min-microvolt = <500000>;
                                regulator-max-microvolt = <3400000>;
                                regulator-enable-ramp-delay = <1000>;
                        };
                        reg_aldo4: aldo4 {
                                regulator-name = "axp8191-aldo4";
                                regulator-min-microvolt = <500000>;
                                regulator-max-microvolt = <3400000>;
                                regulator-enable-ramp-delay = <1000>;
                        };
                        reg_aldo5: aldo5 {
                                regulator-name = "axp8191-aldo5";
                                regulator-min-microvolt = <500000>;
                                regulator-max-microvolt = <3400000>;
                                regulator-enable-ramp-delay = <1000>;
                        };
                        reg_aldo6: aldo6 {
                                regulator-name = "axp8191-aldo6";
                                regulator-min-microvolt = <500000>;
                                regulator-max-microvolt = <3400000>;
                                regulator-enable-ramp-delay = <1000>;
                        };
                        reg_bldo1: bldo1 {
                                regulator-name = "axp8191-bldo1";
                                regulator-min-microvolt = <500000>;
                                regulator-max-microvolt = <3400000>;
                                regulator-enable-ramp-delay = <1000>;
                        };
                        reg_bldo2: bldo2 {
                                regulator-name = "axp8191-bldo2";
                                regulator-min-microvolt = <500000>;
                                regulator-max-microvolt = <3400000>;
                                regulator-enable-ramp-delay = <1000>;
                        };
                        reg_bldo3: bldo3 {
                                regulator-name = "axp8191-bldo3";
                                regulator-min-microvolt = <500000>;
                                regulator-max-microvolt = <3400000>;
                                regulator-enable-ramp-delay = <1000>;
                        };
                        reg_bldo4: bldo4 {
                                regulator-name = "axp8191-bldo4";
                                regulator-min-microvolt = <500000>;
                                regulator-max-microvolt = <3400000>;
                                regulator-enable-ramp-delay = <1000>;
                                regulator-boot-on;
                                regulator-always-on;
                        };
                        reg_bldo5: bldo5 {
                                regulator-name = "axp8191-bldo5";
                                regulator-min-microvolt = <500000>;
                                regulator-max-microvolt = <3400000>;
                                regulator-enable-ramp-delay = <1000>;
                        };
                        reg_cldo1: cldo1 {
                                regulator-name = "axp8191-cldo1";
                                regulator-min-microvolt = <500000>;
                                regulator-max-microvolt = <3500000>;
                                regulator-enable-ramp-delay = <1000>;
                                regulator-boot-on;
                                regulator-always-on;
                        };
                        reg_cldo2: cldo2 {
                                regulator-name = "axp8191-cldo2";
                                regulator-min-microvolt = <500000>;
                                regulator-max-microvolt = <3500000>;
                                regulator-enable-ramp-delay = <1000>;
                                regulator-boot-on;
                                regulator-always-on;
                        };
                        reg_cldo3: cldo3 {
                                regulator-name = "axp8191-cldo3";
                                regulator-min-microvolt = <500000>;
                                regulator-max-microvolt = <3500000>;
                                regulator-enable-ramp-delay = <1000>;
                                regulator-boot-on;
                                regulator-always-on;
                        };
                        reg_cldo4: cldo4 {
                                regulator-name = "axp8191-cldo4";
                                regulator-min-microvolt = <500000>;
                                regulator-max-microvolt = <3500000>;
                                regulator-enable-ramp-delay = <1000>;
                        };
                        reg_cldo5: cldo5 {
                                regulator-name = "axp8191-cldo5";
                                regulator-min-microvolt = <500000>;
                                regulator-max-microvolt = <3400000>;
                                regulator-enable-ramp-delay = <1000>;
                                regulator-boot-on;
                                regulator-always-on;
                        };
                        reg_dldo1: dldo1 {
                                regulator-name = "axp8191-dldo1";
                                regulator-min-microvolt = <500000>;
                                regulator-max-microvolt = <3400000>;
                                regulator-enable-ramp-delay = <1000>;
                                regulator-boot-on;
                                regulator-always-on;
                        };
                        reg_dldo2: dldo2 {
                                regulator-name = "axp8191-dldo2";
                                regulator-min-microvolt = <500000>;
                                regulator-max-microvolt = <3400000>;
                                regulator-enable-ramp-delay = <1000>;
                        };
                        reg_dldo3: dldo3 {
                                regulator-name = "axp8191-dldo3";
                                regulator-min-microvolt = <500000>;
                                regulator-max-microvolt = <3400000>;
                                regulator-enable-ramp-delay = <1000>;
                        };
                        reg_dldo4: dldo4 {
                                regulator-name = "axp8191-dldo4";
                                regulator-min-microvolt = <500000>;
                                regulator-max-microvolt = <3400000>;
                                regulator-enable-ramp-delay = <1000>;
                        };
                        reg_dldo5: dldo5 {
                                regulator-name = "axp8191-dldo5";
                                regulator-min-microvolt = <500000>;
                                regulator-max-microvolt = <3400000>;
                                regulator-enable-ramp-delay = <1000>;
                        };
                        reg_dldo6: dldo6 {
                                regulator-name = "axp8191-dldo6";
                                regulator-min-microvolt = <500000>;
                                regulator-max-microvolt = <3400000>;
                                regulator-enable-ramp-delay = <1000>;
                                regulator-boot-on;
                                regulator-always-on;
                        };
                        reg_eldo1: eldo1 {
                                regulator-name = "axp8191-eldo1";
                                regulator-min-microvolt = <500000>;
                                regulator-max-microvolt = <3400000>;
                                regulator-enable-ramp-delay = <1000>;
                                regulator-boot-on;
                                regulator-always-on;
                        };
                        reg_eldo2: eldo2 {
                                regulator-name = "axp8191-eldo2";
                                regulator-min-microvolt = <500000>;
                                regulator-max-microvolt = <3400000>;
                                regulator-enable-ramp-delay = <1000>;
                                regulator-boot-on;
                                regulator-always-on;
                        };
                        reg_eldo3: eldo3 {
                                regulator-name = "axp8191-eldo3";
                                regulator-min-microvolt = <500000>;
                                regulator-max-microvolt = <3400000>;
                                regulator-enable-ramp-delay = <1000>;
                        };
                        reg_eldo4: eldo4 {
                                regulator-name = "axp8191-eldo4";
                                regulator-min-microvolt = <500000>;
                                regulator-max-microvolt = <3400000>;
                                regulator-enable-ramp-delay = <1000>;
                        };
                        reg_eldo5: eldo5 {
                                regulator-name = "axp8191-eldo5";
                                regulator-min-microvolt = <500000>;
                                regulator-max-microvolt = <3400000>;
                                regulator-enable-ramp-delay = <1000>;
                        };
                        reg_eldo6: eldo6 {
                                regulator-name = "axp8191-eldo6";
                                regulator-min-microvolt = <500000>;
                                regulator-max-microvolt = <3400000>;
                                regulator-enable-ramp-delay = <1000>;
                                regulator-always-on;
                                regulator-boot-on;
                        };
                        reg_dc1sw1: dc1sw1 {
                                regulator-name = "axp8191-dc1sw1";
                                swin-supply = <&reg_dcdc1>;
                                regulator-boot-on;
                                regulator-always-on;
                        };
                        reg_dc1sw2: dc1sw2 {
                                regulator-name = "axp8191-dc1sw2";
                                swin-supply = <&reg_dcdc1>;
                                /* add always-on */
                                regulator-always-on;
                        };
                };

                virtual-dcdc1 {
                        compatible = "xpower-vregulator,dcdc1";
                        dcdc1-supply = <&reg_dcdc1>;
                };
                virtual-dcdc2 {
                        compatible = "xpower-vregulator,dcdc2";
                        dcdc2-supply = <&reg_dcdc2>;
                };
                virtual-dcdc3 {
                        compatible = "xpower-vregulator,dcdc3";
                        dcdc3-supply = <&reg_dcdc3>;
                };
                virtual-dcdc4 {
                        compatible = "xpower-vregulator,dcdc4";
                        dcdc4-supply = <&reg_dcdc4>;
                };
                virtual-dcdc5 {
                        compatible = "xpower-vregulator,dcdc5";
                        dcdc5-supply = <&reg_dcdc5>;
                };
                virtual-dcdc6 {
                        compatible = "xpower-vregulator,dcdc6";
                        dcdc6-supply = <&reg_dcdc6>;
                };
                virtual-dcdc7 {
                        compatible = "xpower-vregulator,dcdc7";
                        dcdc7-supply = <&reg_dcdc7>;
                };
                virtual-dcdc8 {
                        compatible = "xpower-vregulator,dcdc8";
                        dcdc8-supply = <&reg_dcdc8>;
                };
                virtual-dcdc9 {
                        compatible = "xpower-vregulator,dcdc9";
                        dcdc9-supply = <&reg_dcdc9>;
                };
                virtual-rtcldo {
                        compatible = "xpower-vregulator,rtcldo";
                        rtcldo-supply = <&reg_rtcldo>;
                };
                virtual-aldo1 {
                        compatible = "xpower-vregulator,aldo1";
                        aldo1-supply = <&reg_aldo1>;
                };
                virtual-aldo2 {
                        compatible = "xpower-vregulator,aldo2";
                        aldo2-supply = <&reg_aldo2>;
                };
                virtual-aldo3 {
                        compatible = "xpower-vregulator,aldo3";
                        aldo3-supply = <&reg_aldo3>;
                };
                virtual-aldo4 {
                        compatible = "xpower-vregulator,aldo4";
                        aldo4-supply = <&reg_aldo4>;
                };
                virtual-aldo5 {
                        compatible = "xpower-vregulator,aldo5";
                        aldo5-supply = <&reg_aldo5>;
                };
                virtual-aldo6 {
                        compatible = "xpower-vregulator,aldo6";
                        aldo6-supply = <&reg_aldo6>;
                };
                virtual-bldo1 {
                        compatible = "xpower-vregulator,bldo1";
                        bldo1-supply = <&reg_bldo1>;
                };
                virtual-bldo2 {
                        compatible = "xpower-vregulator,bldo2";
                        bldo2-supply = <&reg_bldo2>;
                };
                virtual-bldo3 {
                        compatible = "xpower-vregulator,bldo3";
                        bldo3-supply = <&reg_bldo3>;
                };
                virtual-bldo4 {
                        compatible = "xpower-vregulator,bldo4";
                        bldo4-supply = <&reg_bldo4>;
                };
                virtual-bldo5 {
                        compatible = "xpower-vregulator,bldo5";
                        bldo5-supply = <&reg_bldo5>;
                };
                virtual-cldo1 {
                        compatible = "xpower-vregulator,cldo1";
                        cldo1-supply = <&reg_cldo1>;
                };
                virtual-cldo2 {
                        compatible = "xpower-vregulator,cldo2";
                        cldo2-supply = <&reg_cldo2>;
                };
                virtual-cldo3 {
                        compatible = "xpower-vregulator,cldo3";
                        cldo3-supply = <&reg_cldo3>;
                };
                virtual-cldo4 {
                        compatible = "xpower-vregulator,cldo4";
                        cldo4-supply = <&reg_cldo4>;
                };
                virtual-cldo5 {
                        compatible = "xpower-vregulator,cldo5";
                        cldo5-supply = <&reg_cldo5>;
                };
                virtual-dldo1 {
                        compatible = "xpower-vregulator,dldo1";
                        dldo1-supply = <&reg_dldo1>;
                };
                virtual-dldo2 {
                        compatible = "xpower-vregulator,dldo2";
                        dldo2-supply = <&reg_dldo2>;
                };
                virtual-dldo3 {
                        compatible = "xpower-vregulator,dldo3";
                        dldo3-supply = <&reg_dldo3>;
                };
                virtual-dldo4 {
                        compatible = "xpower-vregulator,dldo4";
                        dldo4-supply = <&reg_dldo4>;
                };
                virtual-dldo5 {
                        compatible = "xpower-vregulator,dldo5";
                        dldo5-supply = <&reg_dldo5>;
                };
                virtual-dldo6 {
                        compatible = "xpower-vregulator,dldo6";
                        dldo6-supply = <&reg_dldo6>;
                };
                virtual-eldo1 {
                        compatible = "xpower-vregulator,eldo1";
                        eldo1-supply = <&reg_eldo1>;
                };
                virtual-eldo2 {
                        compatible = "xpower-vregulator,eldo2";
                        eldo2-supply = <&reg_eldo2>;
                };
                virtual-eldo3 {
                        compatible = "xpower-vregulator,eldo3";
                        eldo3-supply = <&reg_eldo3>;
                };
                virtual-eldo4 {
                        compatible = "xpower-vregulator,eldo4";
                        eldo4-supply = <&reg_eldo4>;
                };
                virtual-eldo5 {
                        compatible = "xpower-vregulator,eldo5";
                        eldo5-supply = <&reg_eldo5>;
                };
                virtual-eldo6 {
                        compatible = "xpower-vregulator,eldo6";
                        eldo6-supply = <&reg_eldo6>;
                };
                virtual-dc1sw1 {
                        compatible = "xpower-vregulator,dc1sw1";
                        dc1sw-supply = <&reg_dc1sw1>;
                };
                virtual-dc1sw2 {
                        compatible = "xpower-vregulator,dc1sw2";
                        dc1sw-supply = <&reg_dc1sw2>;
                };
        };
};

/*Enable soc rtc (was disabled — now needed for hwclock)*/
&rtc {
        status = "okay";
};

&s_twi1 {
        clock-frequency = <400000>;
        pinctrl-0 = <&s_twi1_pins_default>;
        pinctrl-1 = <&s_twi1_pins_sleep>;
        pinctrl-names = "default", "sleep";
        /* For stability and backwards compatibility, we recommend setting ‘twi_drv_used’ to 1 */
        twi_drv_used = <0>;
        no_suspend = <1>;
        status = "disabled";
};

&s_twi2 {
        clock-frequency = <400000>;
        pinctrl-0 = <&s_twi2_pins_default>;
        pinctrl-1 = <&s_twi2_pins_sleep>;
        pinctrl-names = "default", "sleep";
        /* For stability and backwards compatibility, we recommend setting ‘twi_drv_used’ to 1 */
        twi_drv_used = <1>;
        no_suspend = <1>;
        status = "disabled";   /* thinned: no active client (rtc@51 + ac101 both disabled) */

        rtc@51 {
                compatible = "haoyu,hym8563";
                reg = <0x51>;
                #clock-cells = <0>;
                clock-output-names = "xin32k";
                //interrupt-parent = <&pio>;
                //interrupts = <PD 6 IRQ_TYPE_NONE>;
                status = "okay";
        };

        ac101: ac101@1a {
                #sound-dai-cells                = <0>;
                compatible                      = "allwinner,sunxi-ac101";
                reg                             = <0x1a>;
                //pllclk-src                    = "MCLK";
                sysclk-src                      = "MCLK";
                pcm-bit-first                   = "MSB";
                frame-sync-width                = <1>;
                hp-plug-gpio                    = <&r_pio PL 11 GPIO_ACTIVE_HIGH>;
                hp-det-gpio                     = <&pio PB 2 GPIO_ACTIVE_HIGH>;
                jack-det-threshold              = <1>;
                jack-key-det-threshold          = <10>;
                jack-det-debouce-time           = <15>;
                jack-key-det-debouce-time       = <2>;

                /* jack-key-det-voltage = <min max> */
                jack-key-det-voltage-hook       = <23 24>;
                jack-key-det-voltage-up         = <21 22>;
                jack-key-det-voltage-down       = <18 20>;
                // jack-key-det-voltage-voice   = <1 1>;

                /* rglt */
                rglt-max        = <2>;
                rglt0-mode      = "PMU";
                rglt0-voltage   = <3300000>;
                rglt0-supply    = <&reg_aldo5>;

                rglt1-mode      = "PMU";
                rglt1-voltage   = <1800000>;
                rglt1-supply    = <&reg_bldo4>;
                status                  = "disabled";
        };
};


//&dsi0 {
//      status = "disabled";
//      pinctrl-0 = <&dsi0_4lane_pins_a>;
//      pinctrl-1 = <&dsi0_4lane_pins_b>;
//      pinctrl-names = "active","sleep";
//
//      ports {
//              dsi0_out: port@1{
//                      dsi_out_panel: endpoint {
//                              remote-endpoint = <&panel_input>;
//                      };
//              };
//      };
//      panel: panel@0 {
//              compatible = "allwinner,virtual-panel";
//              status = "okay";
//              reg = <0>;
//              ports {
//                      panel_in: port@0 {
//                              reg = <0>;
//                              panel_input: endpoint@0 {
//                                      reg = <0>;
//                                      remote-endpoint = <&dsi_out_panel>;
//                              };
//                      };
//              };
//      };
//};









/* NOTE: &serdes + &combophy0 already configured above (line ~1336).
 * Duplicate block removed to avoid DT merge ambiguity. The earlier
 * &combophy0 reference merges with the base dtsi node, so we don't need
 * to re-declare combophy0 here.
 */

//&xhci2 {
//#ifdef TYPEC_DP
//      phys = <&u2phy>, <&combo0_usb>;
//#else
//      phys = <&u2phy>, <&combo1_usb>;
//#endif
//};


&cpu0 {
        cpu-supply = <&reg_dcdc5>;
};

&dsufreq {
        dsu-supply = <&reg_dcdc5>;
};

&cpu6 {
        cpu-supply = <&reg_dcdc3>;
};

&npu {
        npu-supply = <&reg_dcdc2>;
        status = "disabled";   /* thinned: NPU removed per build spec */
};

&addr_mgt {
        compatible     = "allwinner,sunxi-addr_mgt";
        type_addr_wifi = <0x0>;
        type_addr_bt   = <0x0>;
        type_addr_eth  = <0x0>;
        status         = "disabled";   /* thinned: wifi/bt/eth removed per build spec */
};




/* audio dirver module -> I2S/PCM */









//&i2s4_plat {
//      tdm-num         = <4>;
//      tx-pin          = <1>;
//      rx-pin          = <1>;
//
//      pinctrl-used;
//      pinctrl-names   = "default","sleep";
//      pinctrl-0       = <&i2s4_pins_a &i2s4_pins_b &i2s4_pins_c &i2s4_pins_d &i2s4_pins_e>;
//      pinctrl-1       = <&i2s4_pins_f>;
//
//      tx-hub-en;
//      rx-sync-en;
//      status          = "okay";
//};
//
//&i2s4_mach {
//    soundcard-mach,format           = "i2s";
//    soundcard-mach,frame-master     = <&i2s4_cpu>;
//    soundcard-mach,bitclock-master  = <&i2s4_cpu>;
//    /* soundcard-mach,frame-inversion; */
//    /* soundcard-mach,bitclock-inversion; */
//    soundcard-mach,slot-num         = <2>;
//    soundcard-mach,slot-width       = <32>;
//    soundcard-mach,playback-only;
//    status          = "okay";
//    i2s4_cpu: soundcard-mach,cpu {
//        sound-dai = <&i2s4_plat>;
//        soundcard-mach,pll-fs   = <1>;
//        /* edp mclk: 512fs */
//        soundcard-mach,mclk-fs  = <1>;
//              soundcard-mach,mclk-fp  = <11289600 12288000>;
//    };
//    i2s4_codec: soundcard-mach,codec {
//              soundcard-mach,pll-fs   = <1>;
//              sound-dai               = <&es8388>;
//    };
//};
//
/* audio dirver module -> owa */




&lradc {
        key_cnt = <5>;
        key0 = <210 115>;
        key1 = <410 114>;
        key2 = <590 139>;
        key3 = <750 28>;
        key4 = <880 172>;
        status = "disabled";   /* thinned: LRADC keys removed per build spec */
};

&gpadc0 {
    channel_num = <8>;
        gpadc_mode_select = <0x2>;
    channel_select = <0xff>;
    channel_data_select = <0xff>;
    channel_compare_select = <0x0>;
    channel_cld_select = <0x0>;
    channel_chd_select = <0x0>;
    // channel0_compare_lowdata = <1700000>;
    // channel0_compare_higdata = <1200000>;
    // channel1_compare_lowdata = <460000>;
    // channel1_compare_higdata = <1200000>;
    status = "disabled";   /* thinned: GPADC removed per build spec */
};

&s_irrx {
        pinctrl-names = "default", "sleep";
        pinctrl-0 = <&s_irrx_pins_default>;
        pinctrl-1 = <&s_irrx_pins_sleep>;
        status = "disabled";
};

&spi0 {
        clock-frequency = <50000000>;
        pinctrl-0 = <&spi0_pins_default &spi0_pins_cs>;
        pinctrl-1 = <&spi0_pins_sleep>;
        pinctrl-names = "default", "sleep";
        sunxi,spi-bus-mode = <SUNXI_SPI_BUS_NOR>;
        sunxi,spi-cs-mode = <SUNXI_SPI_CS_SOFT>;
        spi_slave_mode = <0>;
        spi0_cs_bitmap = <1>;
        sunxi,spi-num-cs = <1>;
        spi0_cs_number = <1>;
        status = "disabled";   /* thinned: SPI-NOR flash removed per build spec */

        spidev@0 {
                device_type = "spi_board0";
                compatible = "spi-nor";
                reg = <0x0>;
                spi-max-frequency = <50000000>;
                spi-rx-bus-width = <1>;
                spi-tx-bus-width = <1>;
                m25p,fast-read = <1>;
                status = "disabled";
        };
};

&spi3 {
        clock-frequency = <100000000>;
        pinctrl-names = "default","sleep";
        pinctrl-0 = <&spi3_pin_default>;
        pinctrl-1 = <&spi3_pin_sleep>;

        sunxi,spi-num-cs = <2>;
        sunxi,spi-bus-mode = <SUNXI_SPI_BUS_MASTER>;
        sunxi,spi-cs-mode = <SUNXI_SPI_CS_AUTO>;
        status = "disabled";

        spidev@0 {
                reg = <0>;
                compatible = "rohm,dh2228fv";
                spi-max-frequency = <500000>;
                spi-rx-bus-width = <0x1>;
                spi-tx-bus-width = <0x1>;
        };
        spidev@1 {
                reg = <1>;
                compatible = "rohm,dh2228fv";
                spi-max-frequency = <500000>;
                spi-rx-bus-width = <0x1>;
                spi-tx-bus-width = <0x1>;
        };
};

&ledc  {
        pinctrl-names = "default", "sleep";
        pinctrl-0 = <&ledc_pins_a>;
        pinctrl-1 = <&ledc_pins_b>;
        led_count = <34>;
        output_mode = "GRB";
        reset_ns = <84>;
        t1h_ns = <800>;
        t1l_ns = <320>;
        t0h_ns = <300>;
        t0l_ns = <800>;
        wait_time0_ns = <84>;
        wait_time1_ns = <84>;
        wait_data_time_ns = <600000>;
        status = "disabled";
};

&gpu  {
        gpu-supply = <&reg_dcdc4>;
        status = "disabled";   /* thinned: GPU removed per build spec */
};

&sid {
        sid-supply = <&reg_dldo1>;
        voltage = <1800>;
};

//&vind0 {
//      status = "disabled";
//};
//
//&csi0 {
//      status = "disabled";
//};
//
//&csi1 {
//      status = "disabled";
//};
//
//&csi2 {
//      status = "disabled";
//};
//
//&mipi0 {
//      status = "disabled";
//};
//
//&mipi1 {
//      status = "disabled";
//};
//
//&mipi2 {
//      status = "disabled";
//};
//
//&tdm0 {
//      status = "disabled";
//};
//
//&isp00 {
//      status = "disabled";
//};
//
//&isp01 {
//      status = "disabled";
//};
//
//&isp02 {
//      status = "disabled";
//};
//
//&isp03 {
//      status = "disabled";
//};
//
//&isp10 {
//      status = "disabled";
//};
//
//&isp20 {
//      status = "disabled";
//};
//
//&isp30 {
//      status = "disabled";
//};
//
//&scaler00 {
//      status = "disabled";
//};
//
//&scaler01 {
//      status = "disabled";
//};
//
//&scaler02 {
//      status = "disabled";
//};
//
//&scaler03 {
//      status = "disabled";
//};
//
//&scaler10 {
//      status = "disabled";
//};
//
//&scaler20 {
//      status = "disabled";
//};
//
//&scaler30 {
//      status = "disabled";
//};
//
//&scaler40 {
//      status = "disabled";
//};
//
//&scaler50 {
//      status = "disabled";
//};
//
//&actuator0 {
//      status = "disabled";
//};
//
//&flash0 {
//      status = "disabled";
//};
//
//&sensor0 {
//      status = "disabled";
//};
//
//&sensor1 {
//      status = "disabled";
//};
//
//&sensor2 {
//      status = "disabled";
//};
//
//&sensor_list0 {
//      status = "disabled";
//};
//
//&sensor_list1 {
//      status = "disabled";
//};
//
//&vinc00 {
//      status = "disabled";
//};
//
//&vinc01 {
//      status = "disabled";
//};
//
//&vinc02 {
//      status = "disabled";
//};
//
//&vinc03 {
//      status = "disabled";
//};
//
//&vinc10 {
//      status = "disabled";
//};
//
//&vinc11 {
//      status = "disabled";
//};
//
//&vinc12 {
//      status = "disabled";
//};
//
//&vinc13 {
//      status = "disabled";
//};
//
//&vinc20 {
//      status = "disabled";
//};
//
//&vinc21 {
//      status = "disabled";
//};
//
//&vinc22 {
//      status = "disabled";
//};
//
//&vinc23 {
//      status = "disabled";
//};
//
//&vinc30 {
//      status = "disabled";
//};
//
//&vinc31 {
//      status = "disabled";
//};
//
//&vinc32 {
//      status = "disabled";
//};
//
//&vinc33 {
//      status = "disabled";
//};
//
//&vinc40 {
//      status = "disabled";
//};
//
//&vinc50 {
//      status = "disabled";
//};

&ufs {
       /* thinned: NO UFS CHIP on this board variant. Disabled at boot to
        * silence 67 lines of PHY-timeout spam.
        * Can be enabled at runtime via DT overlay (see overlays/ufs-enable.dtso):
        *   mkdir /sys/kernel/config/device-tree/overlays/ufs-on
        *   cat /lib/firmware/overlays/ufs-enable.dtbo > /sys/kernel/config/device-tree/overlays/ufs-on/dtbo
        */
       vcc-supply = <&reg_dldo6>;
       vccq-supply = <&reg_dcdc8>;
       vccq2-supply = <&reg_dcdc8>;
       status = "disabled";
};

/* thinned: disable power-domain test nodes for removed subsystems
 * (GPU, NPU, PCIe, camera/VI, display, video encoder/decoder) to silence
 * deferred-probe noise and 'runtime_suspend disable clock' warnings.
 * pd_usb2_test left ENABLED (status="okay" from base dtsi) — it's the only
 * consumer of SUN60IW2_PCK_USB2 power domain, which xhci2 needs to probe.
 */
&pd_vi_test       { status = "disabled"; };
&pd_npu_test      { status = "disabled"; };
&pd_gpu_top_test  { status = "disabled"; };
&pd_gpu_core_test { status = "disabled"; };
&pd_pcie_test     { status = "disabled"; };
&pd_de_sys_test   { status = "disabled"; };
&pd_vo_test       { status = "disabled"; };
&pd_vo1_test      { status = "disabled"; };
&pd_ve_dec_test   { status = "disabled"; };
&pd_ve_enc_test   { status = "disabled"; };
/* &pd_usb2_test left at status="okay" — needed for xhci2 to probe */

